# R7FA8M1AH register map
Vendor: Renesas; Series: RA8; File version: 1.2
CPU: CM85 r0p0, little endian, MPU, FPU, VTOR, 4 interrupt priority bits
Registers are 32-bit, read-write, reset 0x0 unless marked. A register's access mark holds for its fields unless they carry their own. Offsets are from the block's base; [hi:lo] are bit positions; {n}, {i} and the like mark numbered series; 'fields as' and 'values as' point back to an identical list.

## ICU — Interrupt Controller
Base 0x4000C000
Same registers: ICU_NS 0x5000C000
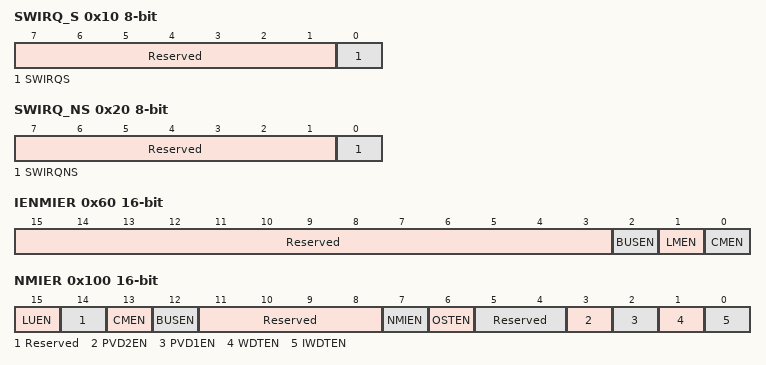
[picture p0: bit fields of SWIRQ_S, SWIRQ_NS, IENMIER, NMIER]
0x10 SWIRQ_S 8-bit — Software Interrupt Request Register for Secure Interrupt
  [7:1] Reserved — These bits are read as 0000000. The write value should be 0000000.
  [0] SWIRQS — Generates an interrupt for the other CPU subsystem.
    0b=(the value of the internal register automatically becomes 0). Writing 0 is ignored.
0x20 SWIRQ_NS 8-bit — Software Interrupt Request Register for Non-secure Interrupt
  [7:1] Reserved — These bits are read as 0000000. The write value should be 0000000.
  [0] SWIRQNS — Generates an interrupt for the other CPU subsystem.
    values as SWIRQ_S.SWIRQS
0x60 IENMIER 16-bit — Integrated Error NMI Interrupt Enable Registe for CPU
  [15:3] Reserved — These bits are read as 0000000000000. The write value should be 0000000000000.
  [2] BUSEN — Integrated BUS error nmi Enable
    0=Disabled; 1=Enabled
  [1] LMEN — Integrated Local Memory error nmi Enable
    0=Disabled; 1=Enabled
  [0] CMEN — Integrated Common Memory error nmi Enable
    0=Disabled; 1=Enabled
0x100 NMIER 16-bit — Non-Maskable Interrupt Enable Register
  [15] LUEN — LockUp Interrupt Enable
    0=Disabled; 1=Enabled
  [14] Reserved — This bit is read as 0. The write value should be 0.
  [13] CMEN — Common Memory error Interrupt Enable
    0=Disabled; 1=Enabled
  [12] BUSEN — BUS error Interrupt Enable
    0=Disabled; 1=Enabled
  [11:8] Reserved — These bits are read as 0000. The write value should be 0000.
  [7] NMIEN — NMI Pin Interrupt Enable
    0=Disabled; 1=Enabled
  [6] OSTEN — Oscillation Stop Detection Interrupt Enable
    0=Disabled; 1=Enabled
  [5:4] Reserved — These bits are read as 00. The write value should be 00.
  [3] PVD2EN — Voltage-Monitoring 2 Interrupt Enable
    0=Disabled; 1=Enabled
  [2] PVD1EN — Voltage-Monitoring 1 Interrupt Enable
    0=Disabled; 1=Enabled
  [1] WDTEN — WDT Underflow/Refresh Error Interrupt Enable
    0=Disabled; 1=Enabled
  [0] IWDTEN — IWDT Underflow/Refresh Error Interrupt Enable
    0=Disabled; 1=Enabled
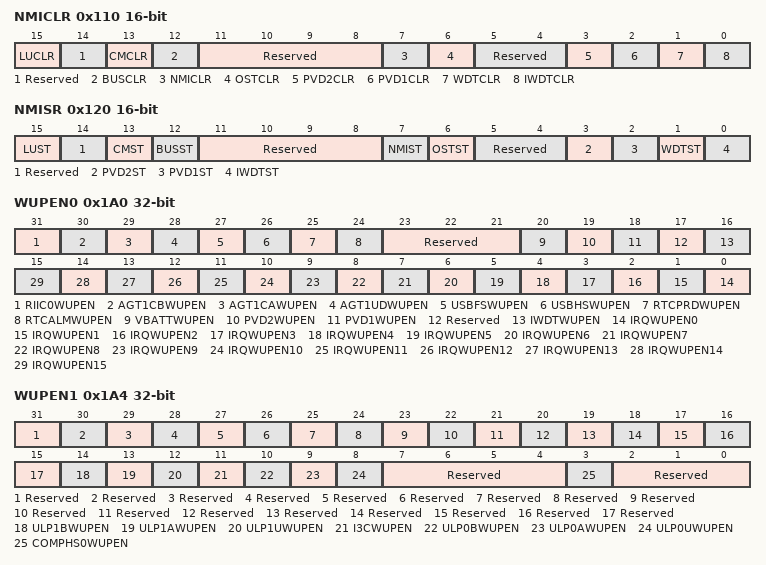
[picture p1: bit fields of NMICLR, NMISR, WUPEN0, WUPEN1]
0x110 NMICLR 16-bit — Non-Maskable Interrupt Status Clear Register
  [15] LUCLR — LU Clear
    0=No effect; 1=Clear the NMISR.LUST flag
  [14] Reserved — This bit is read as 0. The write value should be 0.
  [13] CMCLR — CM Clear
    0=No effect; 1=Clear the NMISR.CMST flag
  [12] BUSCLR — Bus Clear
    0=No effect; 1=Clear the NMISR.BUSST flag
  [11:8] Reserved — These bits are read as 0000. The write value should be 0000.
  [7] NMICLR — NMI Clear
    0=No effect; 1=Clear the NMISR.NMIST flag
  [6] OSTCLR — OST Clear
    0=No effect; 1=Clear the NMISR.OSTST flag
  [5:4] Reserved — These bits are read as 00. The write value should be 00.
  [3] PVD2CLR — PVD2 Clear
    0=No effect; 1=Clear the NMISR.PVD2ST flag
  [2] PVD1CLR — PVD1 Clear
    0=No effect; 1=Clear the NMISR.PVD1ST flag
  [1] WDTCLR — WDT Clear
    0=No effect; 1=Clear the NMISR.WDTST flag
  [0] IWDTCLR — IWDT Clear
    0=No effect; 1=Clear the NMISR.IWDTST flag
0x120 NMISR 16-bit ro — Non-Maskable Interrupt Status Register
  [15] LUST — LockUp Interrupt Status Flag
    0=interrupt not requested; 1=interrupt requested
  [14] Reserved — This bit is read as 0.
  [13] CMST — Common Memory error Interrupt Status Flag
    0=interrupt not requested; 1=interrupt requested
  [12] BUSST — BUS error Interrupt Status Flag
    0=interrupt not requested; 1=interrupt requested
  [11:8] Reserved — These bits are read as 0000.
  [7] NMIST — NMI Status Flag
    0=interrupt not requested; 1=interrupt requested
  [6] OSTST — Oscillation Stop Detection Interrupt Status Flag
    0=interrupt not requested; 1=interrupt requested
  [5:4] Reserved — These bits are read as 00.
  [3] PVD2ST — Voltage-Monitoring 2 Interrupt Status Flag
    0=interrupt not requested; 1=interrupt requested
  [2] PVD1ST — Voltage-Monitoring 1 Interrupt Status Flag
    0=interrupt not requested; 1=interrupt requested
  [1] WDTST — WDT Underflow/Refresh Error Status Flag
    0=interrupt not requested; 1=interrupt requested
  [0] IWDTST — IWDT Underflow/Refresh Error Status Flag
    0=interrupt not requested; 1=interrupt requested
0x1A0 WUPEN0 — Wake Up Interrupt Enable Register 0
  [31] RIIC0WUPEN — RIIC0 Address Match Interrupt Deep Sleep/Software Standby Returns Enable bit
    0=Deep Sleep/Software Standby returns by RIIC0 address match interrupt is disabled; 1=Deep Sleep/Software Standby returns by RIIC0 address match interrupt is enabled
  [30] AGT1CBWUPEN — AGT1 Compare Match B Interrupt Deep Sleep/Software Standby Returns Enable bit
    0=Deep Sleep/Software Standby returns by AGT1 compare match B interrupt is disabled; 1=Deep Sleep/Software Standby returns by AGT1 compare match B interrupt is enabled
  [29] AGT1CAWUPEN — AGT1 Compare Match A Interrupt Deep Sleep/Software Standby Returns Enable bit
    0=Deep Sleep/Software Standby returns by AGT1 compare match A interrupt is disabled; 1=Deep Sleep/Software Standby returns by AGT1 compare match A interrupt is enabled
  [28] AGT1UDWUPEN — AGT1 Underflow Interrupt Deep Sleep/Software Standby Returns Enable bit
    0=Deep Sleep/Software Standby returns by AGT1 underflow interrupt is disabled; 1=Deep Sleep/Software Standby returns by AGT1 underflow interrupt is enabled
  [27] USBFSWUPEN — USBFS0 Interrupt Deep Sleep/Software Standby Returns Enable bit
    0=Deep Sleep/Software Standby returns by USBFS0 interrupt is disabled; 1=Deep Sleep/Software Standby returns by USBFS0 interrupt is enabled
  [26] USBHSWUPEN — USBHS Interrupt Deep Sleep/Software Standby Returns Enable bit
    0=Deep Sleep/Software Standby returns by USBHS interrupt is disabled; 1=Deep Sleep/Software Standby returns by USBHS interrupt is enabled
  [25] RTCPRDWUPEN — RCT Period Interrupt Deep Sleep/Software Standby Returns Enable bit
    0=Deep Sleep/Software Standby returns by RTC period interrupt is disabled; 1=Deep Sleep/Software Standby returns by RTC period interrupt is enabled
  [24] RTCALMWUPEN — RTC Alarm Interrupt Deep Sleep/Software Standby Returns Enable bit
    0=Deep Sleep/Software Standby returns by RTC alarm interrupt is disabled; 1=Deep Sleep/Software Standby returns by RTC alarm interrupt is enabled
  [23:21] Reserved — These bits are read as 000. The write value should be 000.
  [20] VBATTWUPEN — VBATT Monitor Interrupt Deep Sleep/Software Standby Returns Enable bit
    0=Deep Sleep/Software Standby returns by VBATT monitor interrupt is disabled; 1=Deep Sleep/Software Standby returns by VBATT monitor interrupt is enabled
  [19] PVD2WUPEN — PVD2 Interrupt Deep Sleep/Software Standby Returns Enable bit
    0=Deep Sleep/Software Standby returns by PVD2 interrupt is disabled; 1=Deep Sleep/Software Standby returns by PVD2 interrupt is enabled
  [18] PVD1WUPEN — PVD1 Interrupt Deep Sleep/Software Standby Returns Enable bit
    0=Deep Sleep/Software Standby returns by PVD1 interrupt is disabled; 1=Deep Sleep/Software Standby returns by PVD1 interrupt is enabled
  [17] Reserved — This bit is read as 0. The write value should be 0.
  [16] IWDTWUPEN — IWDT Interrupt Deep Sleep/Software Standby Returns Enable bit
    0=Deep Sleep/Software Standby returns by IWDT interrupt is disabled; 1=Deep Sleep/Software Standby returns by IWDT interrupt is enabled
  [n] IRQWUPEN{n} (n=0..15) — IRQ{n} Interrupt Deep Sleep/Software Standby Returns Enable bit
    0=Deep Sleep/Software Standby returns by IRQ{n} interrupt is disabled; 1=Deep Sleep/Software Standby returns by IRQ{n} interrupt is enabled
0x1A4 WUPEN1 — Wake Up Interrupt Enable Register 1
  [31] Reserved — This bit is read as 0. The write value should be 0.
  [30] Reserved — This bit is read as 0. The write value should be 0.
  [29] Reserved — This bit is read as 0. The write value should be 0.
  [28] Reserved — This bit is read as 0. The write value should be 0.
  [27] Reserved — This bit is read as 0. The write value should be 0.
  [26] Reserved — This bit is read as 0. The write value should be 0.
  [25] Reserved — This bit is read as 0. The write value should be 0.
  [24] Reserved — This bit is read as 0. The write value should be 0.
  [23] Reserved — This bit is read as 0. The write value should be 0.
  [22] Reserved — This bit is read as 0. The write value should be 0.
  [21] Reserved — This bit is read as 0. The write value should be 0.
  [20] Reserved — This bit is read as 0. The write value should be 0.
  [19] Reserved — This bit is read as 0. The write value should be 0.
  [18] Reserved — This bit is read as 0. The write value should be 0.
  [17] Reserved — This bit is read as 0. The write value should be 0.
  [16] Reserved — This bit is read as 0. The write value should be 0.
  [15] Reserved — This bit is read as 0. The write value should be 0.
  [14] ULP1BWUPEN — ULPT1 Compare Match B Interrupt Deep Sleep/Software Standby Returns Enable bit
    0=Deep Sleep/Software Standby returns by ULPT1 Compare match B interrupt is disabled; 1=Deep Sleep/Software Standby returns by ULPT1 Compare match B interrupt is enabled
  [13] ULP1AWUPEN — ULPT1 Compare Match A Interrupt Deep Sleep/Software Standby Returns Enable bit
    0=Deep Sleep/Software Standby returns by ULPT1 Compare match A interrupt is disabled; 1=Deep Sleep/Software Standby returns by ULPT1 Compare match A interrupt is enabled
  [12] ULP1UWUPEN — ULPT1 Underflow Interrupt Deep Sleep/Software Standby Returns Enable bit
    0=Deep Sleep/Software Standby returns by ULPT1 Underflow interrupt is disabled; 1=Deep Sleep/Software Standby returns by ULPT1 Underflow interrupt is enabled
  [11] I3CWUPEN — I3C Wakeup Condition Detection Interrupt Deep Sleep/Software Standby Returns Enable bit
    0=Deep Sleep/Software Standby returns by I3C wake up interrupt is disabled; 1=Deep Sleep/Software Standby returns by I3C wake up interrupt is enabled
  [10] ULP0BWUPEN — ULPT0 Compare Match B Interrupt Deep Sleep/Software Standby Returns Enable bit
    0=Deep Sleep/Software Standby returns by ULPT0 Compare match B interrupt is disabled; 1=Deep Sleep/Software Standby returns by ULPT0 Compare match B interrupt is enabled
  [9] ULP0AWUPEN — ULPT0 Compare Match A Interrupt Deep Sleep/Software Standby Returns Enable bit
    0=Deep Sleep/Software Standby returns by ULPT0 Compare match A interrupt is disabled; 1=Deep Sleep/Software Standby returns by ULPT0 Compare match A interrupt is enabled
  [8] ULP0UWUPEN — ULPT0 Underflow Interrupt Deep Sleep/Software Standby Returns Enable bit
    0=Deep Sleep/Software Standby returns by ULPT0 Underflow interrupt is disabled; 1=Deep Sleep/Software Standby returns by ULPT0 Underflow interrupt is enabled
  [7:4] Reserved — These bits are read as 0000. The write value should be 0000.
  [3] COMPHS0WUPEN — Comparator-HS0 Interrupt Deep Sleep/Software Standby Returns Enable bit
    0=Deep Sleep/Software Standby returns by Comparator-HS0 interrupt is disabled; 1=Deep Sleep/Software Standby returns by Comparator-HS0 interrupt is enabled
  [2:0] Reserved — These bits are read as 000. The write value should be 000.
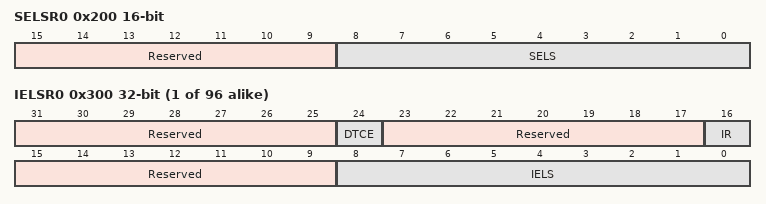
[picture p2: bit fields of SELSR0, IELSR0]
0x200 SELSR0 16-bit — SYS Event Link Setting Register
  [15:9] Reserved — These bits are read as 0000000. The write value should be 0000000.
  [8:0] SELS — SYS Event Link Select
    0=Disable event output to the associated low-power mode module; other=others (Event signal number to be linked.)
{0x300+4i} IELSR{i} (i=0..95) — ICU Event Link Setting Register {i}
  [31:25] Reserved — These bits are read as 0000000. The write value should be 0000000.
  [24] DTCE — DTC Activation Enable
    0=DTC activation is disabled; 1=DTC activation is enabled
  [23:17] Reserved — These bits are read as 0000000. The write value should be 0000000.
  [16] IR — Interrupt Status Flag
    0=No interrupt request is generated; 1=An interrupt request is generated ( "1" write to the IR bit is prohibited. )
  [15:9] Reserved — These bits are read as 0000000. The write value should be 0000000.
  [8:0] IELS — Event selection to NVIC
    0=Nothing is selected; other=others (See Event Table)
